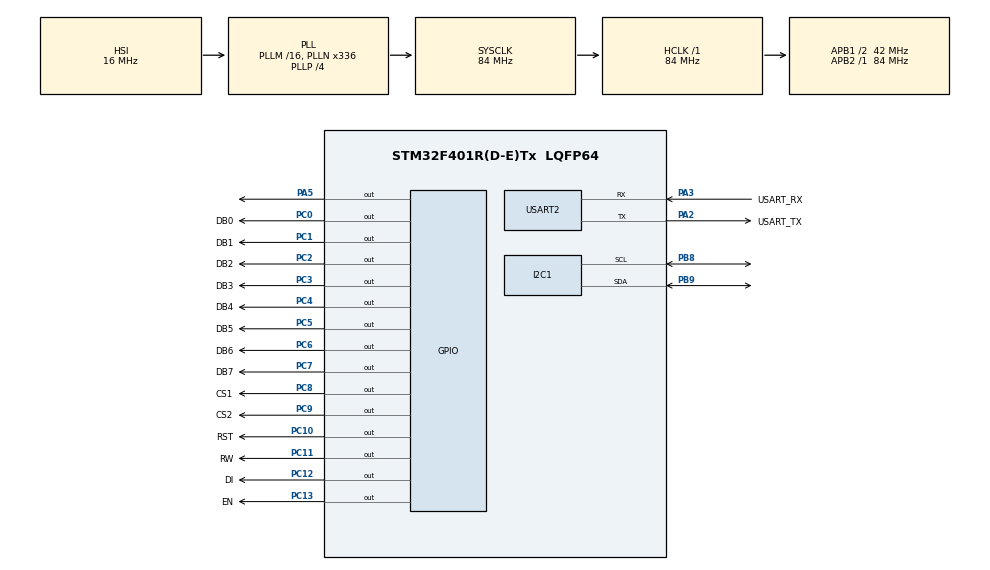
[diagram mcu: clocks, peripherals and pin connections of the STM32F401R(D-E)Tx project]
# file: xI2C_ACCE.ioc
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Mcu.Family=STM32F4
Mcu.Name=STM32F401R(D-E)Tx
Mcu.Package=LQFP64
NVIC.PriorityGroup=NVIC_PRIORITYGROUP_0
PA13.GPIO_Label=TMS
PA13.Signal=SYS_JTMS-SWDIO
PA14.GPIO_Label=TCK
PA14.Signal=SYS_JTCK-SWCLK
PA2.GPIO_Label=USART_TX
PA2.GPIO_Mode=GPIO_MODE_AF_PP
PA2.GPIO_PuPd=GPIO_NOPULL
PA2.GPIO_Speed=GPIO_SPEED_FREQ_LOW
PA2.Mode=Asynchronous
PA2.Signal=USART2_TX
PA3.GPIO_Label=USART_RX
PA3.GPIO_Mode=GPIO_MODE_AF_PP
PA3.GPIO_PuPd=GPIO_NOPULL
PA3.GPIO_Speed=GPIO_SPEED_FREQ_LOW
PA3.Mode=Asynchronous
PA3.Signal=USART2_RX
PA5.Signal=GPIO_Output
PB3.GPIO_Label=SWO
PB3.Signal=SYS_JTDO-SWO
PB8.Mode=I2C
PB8.Signal=I2C1_SCL
PB9.Mode=I2C
PB9.Signal=I2C1_SDA
PC0.GPIO_Label=DB0
PC0.Signal=GPIO_Output
PC1.GPIO_Label=DB1
PC1.Signal=GPIO_Output
PC10.GPIO_Label=RST
PC10.Signal=GPIO_Output
PC11.GPIO_Label=RW
PC11.Signal=GPIO_Output
PC12.GPIO_Label=DI
PC12.Signal=GPIO_Output
PC13-ANTI_TAMP.GPIO_Label=EN
PC13-ANTI_TAMP.Signal=GPIO_Output
PC14-OSC32_IN.Signal=RCC_OSC32_IN
PC15-OSC32_OUT.Signal=RCC_OSC32_OUT
PC2.GPIO_Label=DB2
PC2.Signal=GPIO_Output
PC3.GPIO_Label=DB3
PC3.Signal=GPIO_Output
PC4.GPIO_Label=DB4
PC4.Signal=GPIO_Output
PC5.GPIO_Label=DB5
PC5.Signal=GPIO_Output
PC6.GPIO_Label=DB6
PC6.Signal=GPIO_Output
PC7.GPIO_Label=DB7
PC7.Signal=GPIO_Output
PC8.GPIO_Label=CS1
PC8.Signal=GPIO_Output
PC9.GPIO_Label=CS2
PC9.Signal=GPIO_Output
PH0\ -\ OSC_IN.Signal=RCC_OSC_IN
PH1\ -\ OSC_OUT.Signal=RCC_OSC_OUT
ProjectManager.HeapSize=0x200
ProjectManager.StackSize=0x400
ProjectManager.TargetToolchain=STM32CubeIDE
RCC.AHBFreq_Value=84000000
RCC.APB1CLKDivider=RCC_HCLK_DIV2
RCC.APB1Freq_Value=42000000
RCC.APB1TimFreq_Value=84000000
RCC.APB2Freq_Value=84000000
RCC.APB2TimFreq_Value=84000000
RCC.CortexFreq_Value=84000000
RCC.HCLKFreq_Value=84000000
RCC.HSE_VALUE=8000000
RCC.HSI_VALUE=16000000
RCC.LSE_VALUE=32768
RCC.PLLN=336
RCC.PLLP=RCC_PLLP_DIV4
RCC.PLLQ=7
RCC.SYSCLKFreq_VALUE=84000000
RCC.SYSCLKSource=RCC_SYSCLKSOURCE_PLLCLK
RCC.VCOOutputFreq_Value=336000000
TIM1.Period=0xffff-1
TIM1.Prescaler=84-1
USART2.VirtualMode=VM_ASYNC
VP_TIM1_VS_ClockSourceINT.Mode=Internal
board=NUCLEO-F401RE

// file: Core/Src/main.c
/* USER CODE BEGIN Header */
/**
 ******************************************************************************
 * @file           : main.c
 * @brief          : Main program body
 ******************************************************************************
 * @attention
 *
 * <h2><center>&copy; Copyright (c) 2021 STMicroelectronics.
 * All rights reserved.</center></h2>
 *
 * This software component is licensed by ST under BSD 3-Clause license,
 * the "License"; You may not use this file except in compliance with the
 * License. You may obtain a copy of the License at:
 *                        opensource.org/licenses/BSD-3-Clause
 *
 ******************************************************************************
 */
/* USER CODE END Header */
#include "main.h"

/* USER CODE BEGIN Includes */
#include "app.h"
#include "delay.h"
#include "procedure.h"
/* USER CODE END Includes */

I2C_HandleTypeDef hi2c1;

TIM_HandleTypeDef htim1;

UART_HandleTypeDef huart2;

void SystemClock_Config(void);
static void MX_GPIO_Init(void);
static void MX_USART2_UART_Init(void);
static void MX_I2C1_Init(void);
static void MX_TIM1_Init(void);

int main(void) {

	/* MCU Configuration--------------------------------------------------------*/

	/* Reset of all peripherals, Initializes the Flash interface and the Systick. */
	HAL_Init();

	/* Configure the system clock */
	SystemClock_Config();

	/* Initialize all configured peripherals */
	MX_GPIO_Init();
	MX_USART2_UART_Init();
	MX_I2C1_Init();
	MX_TIM1_Init();
	/* USER CODE BEGIN 2 */
	delay_Init();
	app_init();
	app_game();
	/* USER CODE END 2 */

	/* Infinite loop */
	while (1) {
		app_loop();

	}
}

void SystemClock_Config(void) {
	RCC_OscInitTypeDef RCC_OscInitStruct = { 0 };
	RCC_ClkInitTypeDef RCC_ClkInitStruct = { 0 };

	/** Configure the main internal regulator output voltage
	 */
	__HAL_RCC_PWR_CLK_ENABLE();
	__HAL_PWR_VOLTAGESCALING_CONFIG(PWR_REGULATOR_VOLTAGE_SCALE2);
	/** Initializes the RCC Oscillators according to the specified parameters
	 * in the RCC_OscInitTypeDef structure.
	 */
	RCC_OscInitStruct.OscillatorType = RCC_OSCILLATORTYPE_HSI;
	RCC_OscInitStruct.HSIState = RCC_HSI_ON;
	RCC_OscInitStruct.HSICalibrationValue = RCC_HSICALIBRATION_DEFAULT;
	RCC_OscInitStruct.PLL.PLLState = RCC_PLL_ON;
	RCC_OscInitStruct.PLL.PLLSource = RCC_PLLSOURCE_HSI;
	RCC_OscInitStruct.PLL.PLLM = 16;
	RCC_OscInitStruct.PLL.PLLN = 336;
	RCC_OscInitStruct.PLL.PLLP = RCC_PLLP_DIV4;
	RCC_OscInitStruct.PLL.PLLQ = 7;
	if (HAL_RCC_OscConfig(&RCC_OscInitStruct) != HAL_OK) {
		Error_Handler();
	}
	/** Initializes the CPU, AHB and APB buses clocks
	 */
	RCC_ClkInitStruct.ClockType = RCC_CLOCKTYPE_HCLK | RCC_CLOCKTYPE_SYSCLK
			| RCC_CLOCKTYPE_PCLK1 | RCC_CLOCKTYPE_PCLK2;
	RCC_ClkInitStruct.SYSCLKSource = RCC_SYSCLKSOURCE_PLLCLK;
	RCC_ClkInitStruct.AHBCLKDivider = RCC_SYSCLK_DIV1;
	RCC_ClkInitStruct.APB1CLKDivider = RCC_HCLK_DIV2;
	RCC_ClkInitStruct.APB2CLKDivider = RCC_HCLK_DIV1;

	if (HAL_RCC_ClockConfig(&RCC_ClkInitStruct, FLASH_LATENCY_2) != HAL_OK) {
		Error_Handler();
	}
}

static void MX_I2C1_Init(void) {

	hi2c1.Instance = I2C1;
	hi2c1.Init.ClockSpeed = 100000;
	hi2c1.Init.DutyCycle = I2C_DUTYCYCLE_2;
	hi2c1.Init.OwnAddress1 = 0;
	hi2c1.Init.AddressingMode = I2C_ADDRESSINGMODE_7BIT;
	hi2c1.Init.DualAddressMode = I2C_DUALADDRESS_DISABLE;
	hi2c1.Init.OwnAddress2 = 0;
	hi2c1.Init.GeneralCallMode = I2C_GENERALCALL_DISABLE;
	hi2c1.Init.NoStretchMode = I2C_NOSTRETCH_DISABLE;
	if (HAL_I2C_Init(&hi2c1) != HAL_OK) {
		Error_Handler();
	}

}

static void MX_TIM1_Init(void) {

	TIM_ClockConfigTypeDef sClockSourceConfig = { 0 };
	TIM_MasterConfigTypeDef sMasterConfig = { 0 };

	htim1.Instance = TIM1;
	htim1.Init.Prescaler = 84 - 1;
	htim1.Init.CounterMode = TIM_COUNTERMODE_UP;
	htim1.Init.Period = 0xffff - 1;
	htim1.Init.ClockDivision = TIM_CLOCKDIVISION_DIV1;
	htim1.Init.RepetitionCounter = 0;
	htim1.Init.AutoReloadPreload = TIM_AUTORELOAD_PRELOAD_DISABLE;
	if (HAL_TIM_Base_Init(&htim1) != HAL_OK) {
		Error_Handler();
	}
	sClockSourceConfig.ClockSource = TIM_CLOCKSOURCE_INTERNAL;
	if (HAL_TIM_ConfigClockSource(&htim1, &sClockSourceConfig) != HAL_OK) {
		Error_Handler();
	}
	sMasterConfig.MasterOutputTrigger = TIM_TRGO_RESET;
	sMasterConfig.MasterSlaveMode = TIM_MASTERSLAVEMODE_DISABLE;
	if (HAL_TIMEx_MasterConfigSynchronization(&htim1, &sMasterConfig)
			!= HAL_OK) {
		Error_Handler();
	}

}

static void MX_USART2_UART_Init(void) {

	huart2.Instance = USART2;
	huart2.Init.BaudRate = 115200;
	huart2.Init.WordLength = UART_WORDLENGTH_8B;
	huart2.Init.StopBits = UART_STOPBITS_1;
	huart2.Init.Parity = UART_PARITY_NONE;
	huart2.Init.Mode = UART_MODE_TX_RX;
	huart2.Init.HwFlowCtl = UART_HWCONTROL_NONE;
	huart2.Init.OverSampling = UART_OVERSAMPLING_16;
	if (HAL_UART_Init(&huart2) != HAL_OK) {
		Error_Handler();
	}

}

static void MX_GPIO_Init(void) {
	GPIO_InitTypeDef GPIO_InitStruct = { 0 };

	/* GPIO Ports Clock Enable */
	__HAL_RCC_GPIOC_CLK_ENABLE();
	__HAL_RCC_GPIOH_CLK_ENABLE();
	__HAL_RCC_GPIOA_CLK_ENABLE();
	__HAL_RCC_GPIOB_CLK_ENABLE();

	/*Configure GPIO pin Output Level */
	HAL_GPIO_WritePin(GPIOC,
			EN_Pin | DB0_Pin | DB1_Pin | DB2_Pin | DB3_Pin | DB4_Pin | DB5_Pin
					| DB6_Pin | DB7_Pin | CS1_Pin | CS2_Pin | RST_Pin | RW_Pin
					| DI_Pin, GPIO_PIN_RESET);

	/*Configure GPIO pin Output Level */
	HAL_GPIO_WritePin(GPIOA, GPIO_PIN_5, GPIO_PIN_RESET);

	/*Configure GPIO pins : EN_Pin DB0_Pin DB1_Pin DB2_Pin
	 DB3_Pin DB4_Pin DB5_Pin DB6_Pin
	 DB7_Pin CS1_Pin CS2_Pin RST_Pin
	 RW_Pin DI_Pin */
	GPIO_InitStruct.Pin = EN_Pin | DB0_Pin | DB1_Pin | DB2_Pin | DB3_Pin
			| DB4_Pin | DB5_Pin | DB6_Pin | DB7_Pin | CS1_Pin | CS2_Pin
			| RST_Pin | RW_Pin | DI_Pin;
	GPIO_InitStruct.Mode = GPIO_MODE_OUTPUT_PP;
	GPIO_InitStruct.Pull = GPIO_NOPULL;
	GPIO_InitStruct.Speed = GPIO_SPEED_FREQ_LOW;
	HAL_GPIO_Init(GPIOC, &GPIO_InitStruct);

	/*Configure GPIO pin : PA5 */
	GPIO_InitStruct.Pin = GPIO_PIN_5;
	GPIO_InitStruct.Mode = GPIO_MODE_OUTPUT_PP;
	GPIO_InitStruct.Pull = GPIO_NOPULL;
	GPIO_InitStruct.Speed = GPIO_SPEED_FREQ_LOW;
	HAL_GPIO_Init(GPIOA, &GPIO_InitStruct);

}

void Error_Handler(void) {
	__disable_irq();
	while (1) {
	}
}

/************************ (C) COPYRIGHT STMicroelectronics *****END OF FILE****/
